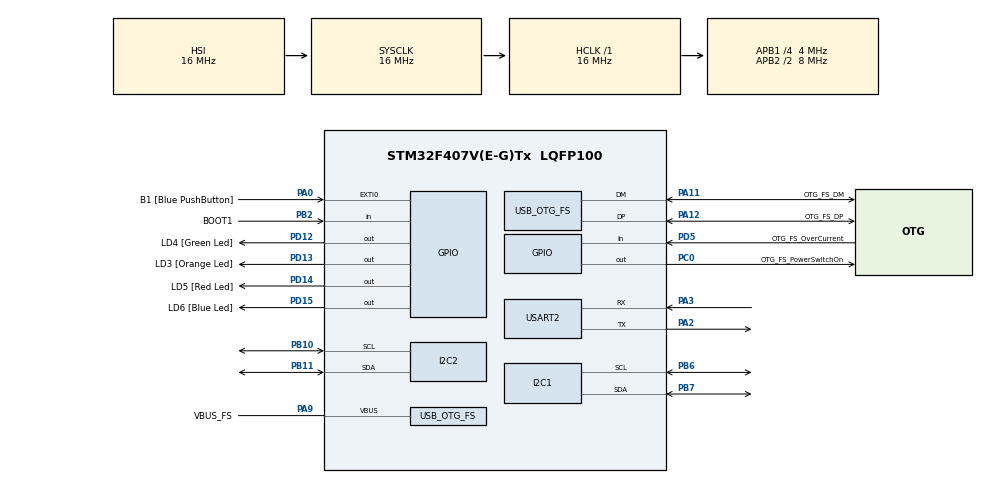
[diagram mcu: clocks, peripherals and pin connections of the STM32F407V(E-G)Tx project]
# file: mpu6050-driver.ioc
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Dma.I2C1_RX.0.Direction=DMA_PERIPH_TO_MEMORY
Dma.I2C1_RX.0.FIFOMode=DMA_FIFOMODE_ENABLE
Dma.I2C1_RX.0.FIFOThreshold=DMA_FIFO_THRESHOLD_FULL
Dma.I2C1_RX.0.Instance=DMA1_Stream0
Dma.I2C1_RX.0.MemBurst=DMA_MBURST_SINGLE
Dma.I2C1_RX.0.MemDataAlignment=DMA_MDATAALIGN_BYTE
Dma.I2C1_RX.0.MemInc=DMA_MINC_ENABLE
Dma.I2C1_RX.0.Mode=DMA_NORMAL
Dma.I2C1_RX.0.PeriphBurst=DMA_PBURST_SINGLE
Dma.I2C1_RX.0.PeriphDataAlignment=DMA_PDATAALIGN_BYTE
Dma.I2C1_RX.0.PeriphInc=DMA_PINC_DISABLE
Dma.I2C1_RX.0.Priority=DMA_PRIORITY_LOW
Dma.Request0=I2C1_RX
I2C1.OwnAddress=0
Mcu.Family=STM32F4
Mcu.Name=STM32F407V(E-G)Tx
Mcu.Package=LQFP100
NVIC.DMA1_Stream0_IRQn=true\:0\:0\:false\:false\:true\:false\:true\:true
NVIC.I2C1_ER_IRQn=true\:0\:0\:false\:false\:true\:true\:true\:true
NVIC.I2C1_EV_IRQn=true\:0\:0\:false\:false\:true\:true\:true\:true
NVIC.OTG_FS_IRQn=true\:0\:0\:false\:false\:true\:true\:true\:true
NVIC.PriorityGroup=NVIC_PRIORITYGROUP_0
PA0-WKUP.GPIO_Label=B1 [Blue PushButton]
PA0-WKUP.GPIO_ModeDefaultEXTI=GPIO_MODE_EVT_RISING
PA0-WKUP.GPIO_PuPd=GPIO_NOPULL
PA0-WKUP.Signal=GPXTI0
PA11.GPIO_Label=OTG_FS_DM
PA11.GPIO_Mode=GPIO_MODE_AF_PP
PA11.GPIO_PuPd=GPIO_NOPULL
PA11.GPIO_Speed=GPIO_SPEED_FREQ_LOW
PA11.Mode=Host_Only
PA11.Signal=USB_OTG_FS_DM
PA12.GPIO_Label=OTG_FS_DP
PA12.GPIO_Mode=GPIO_MODE_AF_PP
PA12.GPIO_PuPd=GPIO_NOPULL
PA12.GPIO_Speed=GPIO_SPEED_FREQ_LOW
PA12.Mode=Host_Only
PA12.Signal=USB_OTG_FS_DP
PA13.GPIO_Label=SWDIO
PA13.Mode=Serial_Wire
PA13.Signal=SYS_JTMS-SWDIO
PA14.GPIO_Label=SWCLK
PA14.Mode=Serial_Wire
PA14.Signal=SYS_JTCK-SWCLK
PA2.Mode=Asynchronous
PA2.Signal=USART2_TX
PA3.Mode=Asynchronous
PA3.Signal=USART2_RX
PA9.GPIO_Label=VBUS_FS
PA9.GPIO_Mode=GPIO_MODE_INPUT
PA9.GPIO_PuPd=GPIO_NOPULL
PA9.Mode=Activate_VBUS
PA9.Signal=USB_OTG_FS_VBUS
PB10.GPIO_Pu=GPIO_PULLUP
PB10.Mode=I2C
PB10.Signal=I2C2_SCL
PB11.GPIO_Pu=GPIO_PULLUP
PB11.Mode=I2C
PB11.Signal=I2C2_SDA
PB2.GPIO_Label=BOOT1
PB2.GPIO_Mode=GPIO_MODE_INPUT
PB2.GPIO_PuPd=GPIO_NOPULL
PB2.Signal=GPIO_Input
PB6.GPIO_Pu=GPIO_PULLUP
PB6.Mode=I2C
PB6.Signal=I2C1_SCL
PB7.GPIO_Pu=GPIO_PULLUP
PB7.Mode=I2C
PB7.Signal=I2C1_SDA
PC0.GPIO_Label=OTG_FS_PowerSwitchOn
PC0.GPIO_PuPd=GPIO_NOPULL
PC0.GPIO_Speed=GPIO_SPEED_FREQ_LOW
PC0.PinState=GPIO_PIN_SET
PC0.Signal=GPIO_Output
PC14-OSC32_IN.GPIO_Label=PC14-OSC32_IN
PC14-OSC32_IN.Mode=LSE-External-Oscillator
PC14-OSC32_IN.Signal=RCC_OSC32_IN
PC15-OSC32_OUT.GPIO_Label=PC15-OSC32_OUT
PC15-OSC32_OUT.Mode=LSE-External-Oscillator
PC15-OSC32_OUT.Signal=RCC_OSC32_OUT
PC3.GPIO_Label=PDM_OUT [MP45DT02_DOUT]
PC3.GPIO_Mode=GPIO_MODE_AF_PP
PC3.GPIO_PuPd=GPIO_NOPULL
PC3.GPIO_Speed=GPIO_SPEED_FREQ_LOW
PC3.Signal=I2S2_SD
PD12.GPIO_Label=LD4 [Green Led]
PD12.GPIO_PuPd=GPIO_NOPULL
PD12.GPIO_Speed=GPIO_SPEED_FREQ_LOW
PD12.Signal=GPIO_Output
PD13.GPIO_Label=LD3 [Orange Led]
PD13.GPIO_PuPd=GPIO_NOPULL
PD13.GPIO_Speed=GPIO_SPEED_FREQ_LOW
PD13.Signal=GPIO_Output
PD14.GPIO_Label=LD5 [Red Led]
PD14.GPIO_PuPd=GPIO_NOPULL
PD14.GPIO_Speed=GPIO_SPEED_FREQ_LOW
PD14.Signal=GPIO_Output
PD15.GPIO_Label=LD6 [Blue Led]
PD15.GPIO_PuPd=GPIO_NOPULL
PD15.GPIO_Speed=GPIO_SPEED_FREQ_LOW
PD15.Signal=GPIO_Output
PD5.GPIO_Label=OTG_FS_OverCurrent
PD5.GPIO_Mode=GPIO_MODE_INPUT
PD5.GPIO_PuPd=GPIO_NOPULL
PD5.Signal=GPIO_Input
PH0-OSC_IN.GPIO_Label=PH0-OSC_IN
PH0-OSC_IN.Mode=HSE-External-Oscillator
PH0-OSC_IN.Signal=RCC_OSC_IN
PH1-OSC_OUT.GPIO_Label=PH1-OSC_OUT
PH1-OSC_OUT.Mode=HSE-External-Oscillator
PH1-OSC_OUT.Signal=RCC_OSC_OUT
ProjectManager.HeapSize=0x200
ProjectManager.StackSize=0x400
ProjectManager.TargetToolchain=STM32CubeIDE
RCC.48MHZClocksFreq_Value=48000000
RCC.AHBFreq_Value=16000000
RCC.APB1CLKDivider=RCC_HCLK_DIV4
RCC.APB1Freq_Value=4000000
RCC.APB1TimFreq_Value=8000000
RCC.APB2CLKDivider=RCC_HCLK_DIV2
RCC.APB2Freq_Value=8000000
RCC.APB2TimFreq_Value=16000000
RCC.CortexFreq_Value=16000000
RCC.HCLKFreq_Value=16000000
RCC.HSE_VALUE=8000000
RCC.HSI_VALUE=16000000
RCC.PLLM=8
RCC.PLLN=336
RCC.PLLQ=7
RCC.SYSCLKFreq_VALUE=16000000
RCC.VCOOutputFreq_Value=336000000
USART2.VirtualMode=VM_ASYNC
USB_HOST.BSP.number=1
USB_HOST.USBH_HandleTypeDef-CDC_FS=hUsbHostFS
USB_HOST.VirtualModeFS=Cdc
USB_HOST0.BSP.STBoard=false
USB_HOST0.BSP.api=Unknown
USB_HOST0.BSP.instance=PC0
USB_HOST0.BSP.ip=GPIO
USB_HOST0.BSP.mode=Output
USB_HOST0.BSP.name=Drive_VBUS_FS
USB_HOST0.BSP.solution=PC0
USB_OTG_FS.VirtualMode=Host_Only
USB_OTG_FS.phy_itface=HCD_PHY_EMBEDDED
VP_USB_HOST_VS_USB_HOST_CDC_FS.Mode=CDC_FS
board=STM32F407G-DISC1

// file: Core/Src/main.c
/* USER CODE BEGIN Header */
/**
 ******************************************************************************
 * @file           : main.c
 * @brief          : Main program body
 ******************************************************************************
 * @attention
 *
 * Copyright (c) 2023 STMicroelectronics.
 * All rights reserved.
 *
 * This software is licensed under terms that can be found in the LICENSE file
 * in the root directory of this software component.
 * If no LICENSE file comes with this software, it is provided AS-IS.
 *
 ******************************************************************************
 */
/* USER CODE END Header */
#include "main.h"
#include "usb_host.h"

/* USER CODE BEGIN Includes */
#include <stdio.h>
#include "app.h"
/* USER CODE END Includes */

I2C_HandleTypeDef hi2c1;
I2C_HandleTypeDef hi2c2;
DMA_HandleTypeDef hdma_i2c1_rx;

UART_HandleTypeDef huart2;

void SystemClock_Config(void);
static void MX_GPIO_Init(void);
static void MX_DMA_Init(void);
static void MX_I2C1_Init(void);
static void MX_USART2_UART_Init(void);
static void MX_I2C2_Init(void);
void MX_USB_HOST_Process(void);

/* USER CODE BEGIN PFP */

#ifdef __GNUC__
#define PUTCHAR_PROTOTYPE int __io_putchar(int ch)
#else
#define PUTCHAR_PROTOTYPE int fputc(int ch,FILE *f)
#endif

PUTCHAR_PROTOTYPE{
	HAL_UART_Transmit(&huart2, (uint8_t *)&ch	, 1, HAL_MAX_DELAY);
	return ch;
}

/* USER CODE END PFP */

int main(void)
{

  /* MCU Configuration--------------------------------------------------------*/

  /* Reset of all peripherals, Initializes the Flash interface and the Systick. */
  HAL_Init();

  /* Configure the system clock */
  SystemClock_Config();

  /* Initialize all configured peripherals */
  MX_GPIO_Init();
  MX_DMA_Init();
  MX_USB_HOST_Init();
  MX_I2C1_Init();
  MX_USART2_UART_Init();
  MX_I2C2_Init();
  /* USER CODE BEGIN 2 */
	app_Init();
  /* USER CODE END 2 */

  /* Infinite loop */
	while (1) {
    MX_USB_HOST_Process();

    /* USER CODE BEGIN 3 */
		app_ProcessLoop();

	}
  /* USER CODE END 3 */
}

void SystemClock_Config(void)
{
  RCC_OscInitTypeDef RCC_OscInitStruct = {0};
  RCC_ClkInitTypeDef RCC_ClkInitStruct = {0};

  /** Configure the main internal regulator output voltage
  */
  __HAL_RCC_PWR_CLK_ENABLE();
  __HAL_PWR_VOLTAGESCALING_CONFIG(PWR_REGULATOR_VOLTAGE_SCALE1);

  /** Initializes the RCC Oscillators according to the specified parameters
  * in the RCC_OscInitTypeDef structure.
  */
  RCC_OscInitStruct.OscillatorType = RCC_OSCILLATORTYPE_HSI|RCC_OSCILLATORTYPE_HSE;
  RCC_OscInitStruct.HSEState = RCC_HSE_ON;
  RCC_OscInitStruct.HSIState = RCC_HSI_ON;
  RCC_OscInitStruct.HSICalibrationValue = RCC_HSICALIBRATION_DEFAULT;
  RCC_OscInitStruct.PLL.PLLState = RCC_PLL_ON;
  RCC_OscInitStruct.PLL.PLLSource = RCC_PLLSOURCE_HSE;
  RCC_OscInitStruct.PLL.PLLM = 8;
  RCC_OscInitStruct.PLL.PLLN = 336;
  RCC_OscInitStruct.PLL.PLLP = RCC_PLLP_DIV2;
  RCC_OscInitStruct.PLL.PLLQ = 7;
  if (HAL_RCC_OscConfig(&RCC_OscInitStruct) != HAL_OK)
  {
    Error_Handler();
  }

  /** Initializes the CPU, AHB and APB buses clocks
  */
  RCC_ClkInitStruct.ClockType = RCC_CLOCKTYPE_HCLK|RCC_CLOCKTYPE_SYSCLK
                              |RCC_CLOCKTYPE_PCLK1|RCC_CLOCKTYPE_PCLK2;
  RCC_ClkInitStruct.SYSCLKSource = RCC_SYSCLKSOURCE_HSI;
  RCC_ClkInitStruct.AHBCLKDivider = RCC_SYSCLK_DIV1;
  RCC_ClkInitStruct.APB1CLKDivider = RCC_HCLK_DIV4;
  RCC_ClkInitStruct.APB2CLKDivider = RCC_HCLK_DIV2;

  if (HAL_RCC_ClockConfig(&RCC_ClkInitStruct, FLASH_LATENCY_0) != HAL_OK)
  {
    Error_Handler();
  }
}

static void MX_I2C1_Init(void)
{

  hi2c1.Instance = I2C1;
  hi2c1.Init.ClockSpeed = 100000;
  hi2c1.Init.DutyCycle = I2C_DUTYCYCLE_2;
  hi2c1.Init.OwnAddress1 = 0;
  hi2c1.Init.AddressingMode = I2C_ADDRESSINGMODE_7BIT;
  hi2c1.Init.DualAddressMode = I2C_DUALADDRESS_DISABLE;
  hi2c1.Init.OwnAddress2 = 0;
  hi2c1.Init.GeneralCallMode = I2C_GENERALCALL_DISABLE;
  hi2c1.Init.NoStretchMode = I2C_NOSTRETCH_DISABLE;
  if (HAL_I2C_Init(&hi2c1) != HAL_OK)
  {
    Error_Handler();
  }

}

static void MX_I2C2_Init(void)
{

  hi2c2.Instance = I2C2;
  hi2c2.Init.ClockSpeed = 100000;
  hi2c2.Init.DutyCycle = I2C_DUTYCYCLE_2;
  hi2c2.Init.OwnAddress1 = 0;
  hi2c2.Init.AddressingMode = I2C_ADDRESSINGMODE_7BIT;
  hi2c2.Init.DualAddressMode = I2C_DUALADDRESS_DISABLE;
  hi2c2.Init.OwnAddress2 = 0;
  hi2c2.Init.GeneralCallMode = I2C_GENERALCALL_DISABLE;
  hi2c2.Init.NoStretchMode = I2C_NOSTRETCH_DISABLE;
  if (HAL_I2C_Init(&hi2c2) != HAL_OK)
  {
    Error_Handler();
  }

}

static void MX_USART2_UART_Init(void)
{

  huart2.Instance = USART2;
  huart2.Init.BaudRate = 115200;
  huart2.Init.WordLength = UART_WORDLENGTH_8B;
  huart2.Init.StopBits = UART_STOPBITS_1;
  huart2.Init.Parity = UART_PARITY_NONE;
  huart2.Init.Mode = UART_MODE_TX_RX;
  huart2.Init.HwFlowCtl = UART_HWCONTROL_NONE;
  huart2.Init.OverSampling = UART_OVERSAMPLING_16;
  if (HAL_UART_Init(&huart2) != HAL_OK)
  {
    Error_Handler();
  }

}

static void MX_DMA_Init(void)
{

  /* DMA controller clock enable */
  __HAL_RCC_DMA1_CLK_ENABLE();

  /* DMA interrupt init */
  /* DMA1_Stream0_IRQn interrupt configuration */
  HAL_NVIC_SetPriority(DMA1_Stream0_IRQn, 0, 0);
  HAL_NVIC_EnableIRQ(DMA1_Stream0_IRQn);

}

static void MX_GPIO_Init(void)
{
  GPIO_InitTypeDef GPIO_InitStruct = {0};

  /* GPIO Ports Clock Enable */
  __HAL_RCC_GPIOC_CLK_ENABLE();
  __HAL_RCC_GPIOH_CLK_ENABLE();
  __HAL_RCC_GPIOA_CLK_ENABLE();
  __HAL_RCC_GPIOB_CLK_ENABLE();
  __HAL_RCC_GPIOD_CLK_ENABLE();

  /*Configure GPIO pin Output Level */
  HAL_GPIO_WritePin(OTG_FS_PowerSwitchOn_GPIO_Port, OTG_FS_PowerSwitchOn_Pin, GPIO_PIN_SET);

  /*Configure GPIO pin Output Level */
  HAL_GPIO_WritePin(GPIOD, LD4_Pin|LD3_Pin|LD5_Pin|LD6_Pin, GPIO_PIN_RESET);

  /*Configure GPIO pin : OTG_FS_PowerSwitchOn_Pin */
  GPIO_InitStruct.Pin = OTG_FS_PowerSwitchOn_Pin;
  GPIO_InitStruct.Mode = GPIO_MODE_OUTPUT_PP;
  GPIO_InitStruct.Pull = GPIO_NOPULL;
  GPIO_InitStruct.Speed = GPIO_SPEED_FREQ_LOW;
  HAL_GPIO_Init(OTG_FS_PowerSwitchOn_GPIO_Port, &GPIO_InitStruct);

  /*Configure GPIO pin : PDM_OUT_Pin */
  GPIO_InitStruct.Pin = PDM_OUT_Pin;
  GPIO_InitStruct.Mode = GPIO_MODE_AF_PP;
  GPIO_InitStruct.Pull = GPIO_NOPULL;
  GPIO_InitStruct.Speed = GPIO_SPEED_FREQ_LOW;
  GPIO_InitStruct.Alternate = GPIO_AF5_SPI2;
  HAL_GPIO_Init(PDM_OUT_GPIO_Port, &GPIO_InitStruct);

  /*Configure GPIO pin : B1_Pin */
  GPIO_InitStruct.Pin = B1_Pin;
  GPIO_InitStruct.Mode = GPIO_MODE_EVT_RISING;
  GPIO_InitStruct.Pull = GPIO_NOPULL;
  HAL_GPIO_Init(B1_GPIO_Port, &GPIO_InitStruct);

  /*Configure GPIO pin : BOOT1_Pin */
  GPIO_InitStruct.Pin = BOOT1_Pin;
  GPIO_InitStruct.Mode = GPIO_MODE_INPUT;
  GPIO_InitStruct.Pull = GPIO_NOPULL;
  HAL_GPIO_Init(BOOT1_GPIO_Port, &GPIO_InitStruct);

  /*Configure GPIO pins : LD4_Pin LD3_Pin LD5_Pin LD6_Pin */
  GPIO_InitStruct.Pin = LD4_Pin|LD3_Pin|LD5_Pin|LD6_Pin;
  GPIO_InitStruct.Mode = GPIO_MODE_OUTPUT_PP;
  GPIO_InitStruct.Pull = GPIO_NOPULL;
  GPIO_InitStruct.Speed = GPIO_SPEED_FREQ_LOW;
  HAL_GPIO_Init(GPIOD, &GPIO_InitStruct);

  /*Configure GPIO pin : OTG_FS_OverCurrent_Pin */
  GPIO_InitStruct.Pin = OTG_FS_OverCurrent_Pin;
  GPIO_InitStruct.Mode = GPIO_MODE_INPUT;
  GPIO_InitStruct.Pull = GPIO_NOPULL;
  HAL_GPIO_Init(OTG_FS_OverCurrent_GPIO_Port, &GPIO_InitStruct);

}

void Error_Handler(void)
{
	__disable_irq();
	while (1) {
	}
}
